# ESP32-S31 register map
Vendor: ESPRESSIF SYSTEMS (SHANGHAI) CO., LTD.; Series: ESP32 S-Series; File version: 1
CPU: RV32IMAFC r0p0, little endian, no MPU, FPU, 0 interrupt priority bits
Address unit: 32 bits
Registers are 32-bit, read-write, reset 0x0 unless marked. A register's access mark holds for its fields unless they carry their own. Offsets are from the block's base; [hi:lo] are bit positions; {n}, {i} and the like mark numbered series; 'fields as' and 'values as' point back to an identical list.

## MEMSPI2 — Memory SPI 2
Base 0x20502000
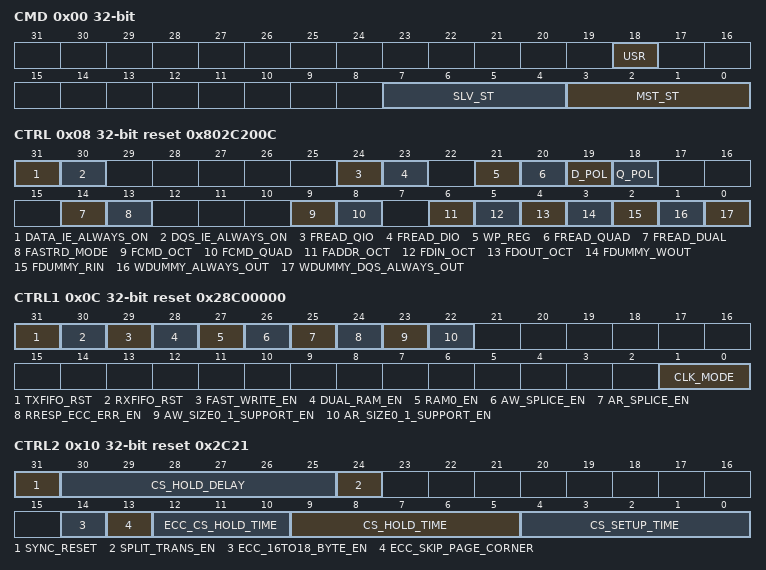
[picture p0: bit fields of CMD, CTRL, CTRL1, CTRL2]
0x00 CMD ro — SPI0 FSM status register
  [18] USR, [7:4] SLV_ST, [3:0] MST_ST
0x08 CTRL reset 0x802C200C — SPI0 control register.
  [31] DATA_IE_ALWAYS_ON, [30] DQS_IE_ALWAYS_ON, [24] FREAD_QIO, [23] FREAD_DIO, [21] WP_REG, [20] FREAD_QUAD, [19] D_POL, [18] Q_POL, [14] FREAD_DUAL, [13] FASTRD_MODE, [9] FCMD_OCT, [8] FCMD_QUAD, [6] FADDR_OCT, [5] FDIN_OCT, [4] FDOUT_OCT, [3] FDUMMY_WOUT, [2] FDUMMY_RIN, [1] WDUMMY_ALWAYS_OUT, [0] WDUMMY_DQS_ALWAYS_OUT
0x0C CTRL1 access per field reset 0x28C00000 — SPI0 control1 register.
  [31] TXFIFO_RST wo, [30] RXFIFO_RST wo, [29] FAST_WRITE_EN rw, [28] DUAL_RAM_EN ro, [27] RAM0_EN ro, [26] AW_SPLICE_EN rw, [25] AR_SPLICE_EN rw, [24] RRESP_ECC_ERR_EN rw, [23] AW_SIZE0_1_SUPPORT_EN rw, [22] AR_SIZE0_1_SUPPORT_EN rw, [1:0] CLK_MODE rw
0x10 CTRL2 access per field reset 0x2C21 — SPI0 control2 register.
  [31] SYNC_RESET wo, [30:25] CS_HOLD_DELAY rw, [24] SPLIT_TRANS_EN rw, [14] ECC_16TO18_BYTE_EN rw, [13] ECC_SKIP_PAGE_CORNER rw, [12:10] ECC_CS_HOLD_TIME rw, [9:5] CS_HOLD_TIME rw, [4:0] CS_SETUP_TIME rw
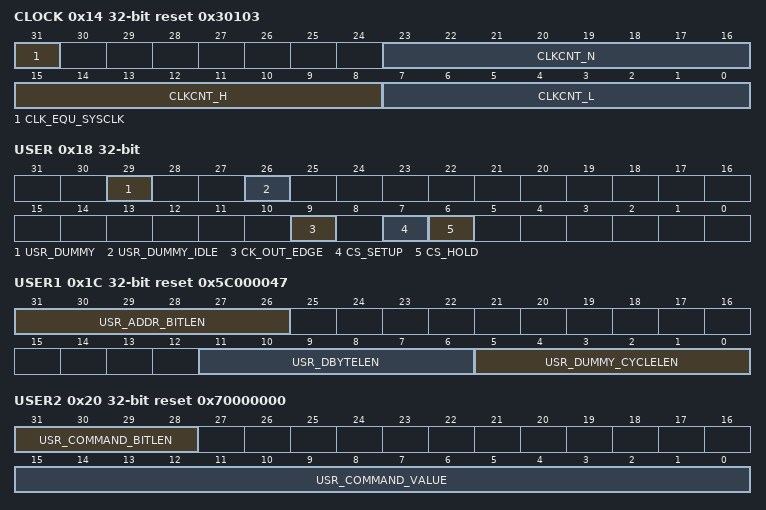
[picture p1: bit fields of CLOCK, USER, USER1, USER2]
0x14 CLOCK reset 0x30103 — SPI clock division control register.
  [31] CLK_EQU_SYSCLK, [23:16] CLKCNT_N, [15:8] CLKCNT_H, [7:0] CLKCNT_L
0x18 USER — SPI0 user register.
  [29] USR_DUMMY, [26] USR_DUMMY_IDLE, [9] CK_OUT_EDGE, [7] CS_SETUP, [6] CS_HOLD
0x1C USER1 access per field reset 0x5C000047 — SPI0 user1 register.
  [31:26] USR_ADDR_BITLEN rw, [11:6] USR_DBYTELEN ro, [5:0] USR_DUMMY_CYCLELEN rw
0x20 USER2 reset 0x70000000 — SPI0 user2 register.
  [31:28] USR_COMMAND_BITLEN, [15:0] USR_COMMAND_VALUE
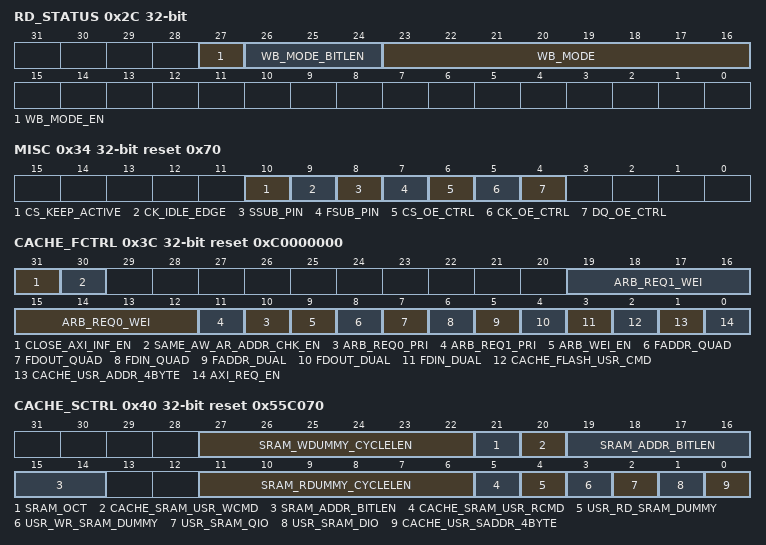
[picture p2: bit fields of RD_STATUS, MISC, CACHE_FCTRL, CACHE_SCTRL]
0x2C RD_STATUS — SPI0 read control register.
  [27] WB_MODE_EN, [26:24] WB_MODE_BITLEN, [23:16] WB_MODE
0x34 MISC access per field reset 0x70 — SPI0 misc register
  [10] CS_KEEP_ACTIVE rw, [9] CK_IDLE_EDGE rw, [8] SSUB_PIN ro, [7] FSUB_PIN ro, [6] CS_OE_CTRL rw, [5] CK_OE_CTRL rw, [4] DQ_OE_CTRL rw
0x3C CACHE_FCTRL reset 0xC0000000 — SPI0 bit mode control register.
  [31] CLOSE_AXI_INF_EN, [30] SAME_AW_AR_ADDR_CHK_EN, [4n+15:4n+12] ARB_REQ{n}_WEI (n=0..1), [n+10] ARB_REQ{n}_PRI (n=0..1), [9] ARB_WEI_EN, [8] FADDR_QUAD, [7] FDOUT_QUAD, [6] FDIN_QUAD, [5] FADDR_DUAL, [4] FDOUT_DUAL, [3] FDIN_DUAL, [2] CACHE_FLASH_USR_CMD, [1] CACHE_USR_ADDR_4BYTE, [0] AXI_REQ_EN
0x40 CACHE_SCTRL reset 0x55C070 — SPI0 external RAM control register
  [27:22] SRAM_WDUMMY_CYCLELEN, [21] SRAM_OCT, [20] CACHE_SRAM_USR_WCMD, [19:14] SRAM_ADDR_BITLEN, [11:6] SRAM_RDUMMY_CYCLELEN, [5] CACHE_SRAM_USR_RCMD, [4] USR_RD_SRAM_DUMMY, [3] USR_WR_SRAM_DUMMY, [2] USR_SRAM_QIO, [1] USR_SRAM_DIO, [0] CACHE_USR_SADDR_4BYTE
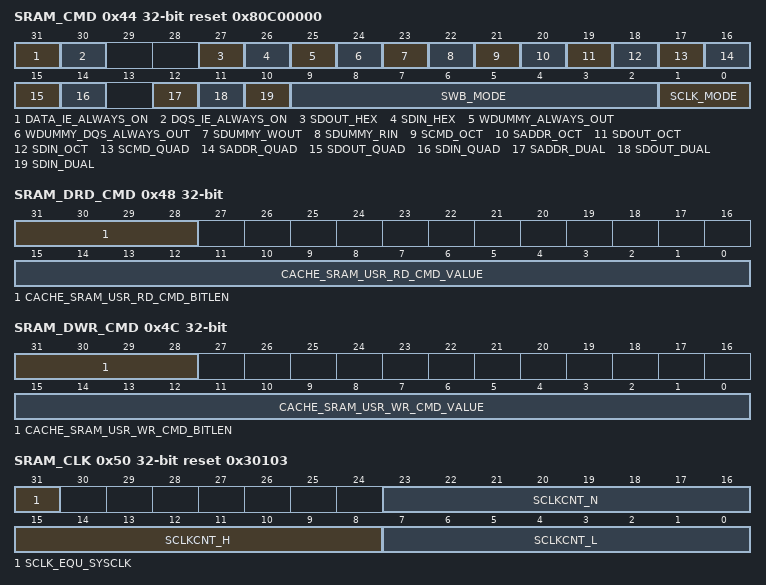
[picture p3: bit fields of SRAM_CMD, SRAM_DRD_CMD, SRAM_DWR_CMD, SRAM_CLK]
0x44 SRAM_CMD reset 0x80C00000 — SPI0 external RAM mode control register
  [31] DATA_IE_ALWAYS_ON, [30] DQS_IE_ALWAYS_ON, [27] SDOUT_HEX, [26] SDIN_HEX, [25] WDUMMY_ALWAYS_OUT, [24] WDUMMY_DQS_ALWAYS_OUT, [23] SDUMMY_WOUT, [22] SDUMMY_RIN, [21] SCMD_OCT, [20] SADDR_OCT, [19] SDOUT_OCT, [18] SDIN_OCT, [17] SCMD_QUAD, [16] SADDR_QUAD, [15] SDOUT_QUAD, [14] SDIN_QUAD, [12] SADDR_DUAL, [11] SDOUT_DUAL, [10] SDIN_DUAL, [9:2] SWB_MODE, [1:0] SCLK_MODE
0x48 SRAM_DRD_CMD — SPI0 external RAM DDR read command control register
  [31:28] CACHE_SRAM_USR_RD_CMD_BITLEN, [15:0] CACHE_SRAM_USR_RD_CMD_VALUE
0x4C SRAM_DWR_CMD — SPI0 external RAM DDR write command control register
  [31:28] CACHE_SRAM_USR_WR_CMD_BITLEN, [15:0] CACHE_SRAM_USR_WR_CMD_VALUE
0x50 SRAM_CLK reset 0x30103 — SPI0 external RAM clock control register
  [31] SCLK_EQU_SYSCLK, [23:16] SCLKCNT_N, [15:8] SCLKCNT_H, [7:0] SCLKCNT_L
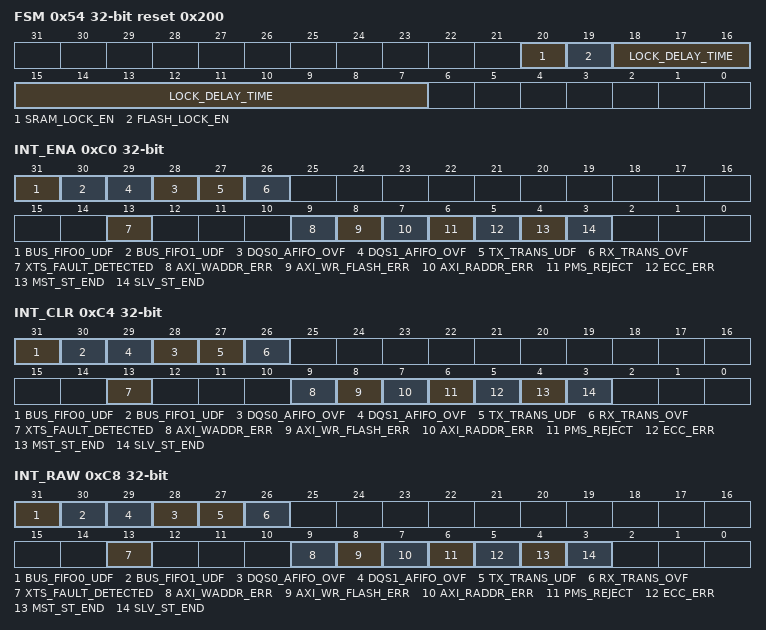
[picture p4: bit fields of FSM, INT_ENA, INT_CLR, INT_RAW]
0x54 FSM reset 0x200 — SPI0 FSM status register
  [20] SRAM_LOCK_EN, [19] FLASH_LOCK_EN, [18:7] LOCK_DELAY_TIME
0xC0 INT_ENA — SPI0 interrupt enable register
  [31] BUS_FIFO0_UDF, [30] BUS_FIFO1_UDF, [n+28] DQS{n}_AFIFO_OVF (n=0..1), [27] TX_TRANS_UDF, [26] RX_TRANS_OVF, [13] XTS_FAULT_DETECTED, [9] AXI_WADDR_ERR, [8] AXI_WR_FLASH_ERR, [7] AXI_RADDR_ERR, [6] PMS_REJECT, [5] ECC_ERR, [4] MST_ST_END, [3] SLV_ST_END
0xC4 INT_CLR wo — SPI0 interrupt clear register
  [31] BUS_FIFO0_UDF write-1-clears, [30] BUS_FIFO1_UDF write-1-clears, [n+28] DQS{n}_AFIFO_OVF (n=0..1) write-1-clears, [27] TX_TRANS_UDF write-1-clears, [26] RX_TRANS_OVF write-1-clears, [13] XTS_FAULT_DETECTED write-1-clears, [9] AXI_WADDR_ERR write-1-clears, [8] AXI_WR_FLASH_ERR write-1-clears, [7] AXI_RADDR_ERR write-1-clears, [6] PMS_REJECT write-1-clears, [5] ECC_ERR write-1-clears, [4] MST_ST_END write-1-clears, [3] SLV_ST_END write-1-clears
0xC8 INT_RAW — SPI0 interrupt raw register
  fields as INT_ENA
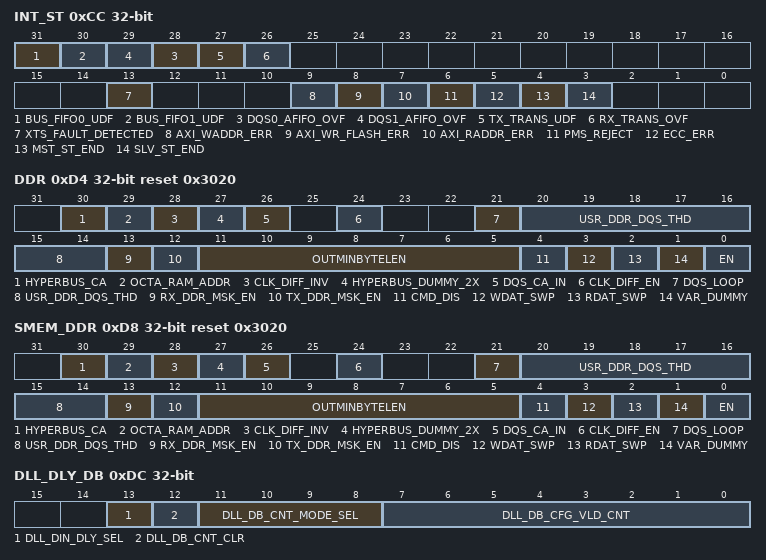
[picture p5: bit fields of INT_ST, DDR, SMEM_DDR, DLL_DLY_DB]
0xCC INT_ST ro — SPI0 interrupt status register
  fields as INT_ENA
0xD4 DDR reset 0x3020 — SPI0 flash DDR mode control register
  [30] HYPERBUS_CA, [29] OCTA_RAM_ADDR, [28] CLK_DIFF_INV, [27] HYPERBUS_DUMMY_2X, [26] DQS_CA_IN, [24] CLK_DIFF_EN, [21] DQS_LOOP, [20:14] USR_DDR_DQS_THD, [13] RX_DDR_MSK_EN, [12] TX_DDR_MSK_EN, [11:5] OUTMINBYTELEN, [4] CMD_DIS, [3] WDAT_SWP, [2] RDAT_SWP, [1] VAR_DUMMY, [0] EN
0xD8 SMEM_DDR reset 0x3020 — SPI0 external RAM DDR mode control register
  fields as DDR
0xDC DLL_DLY_DB — MSPI DLL function and debug configuration register
  [13] DLL_DIN_DLY_SEL, [12] DLL_DB_CNT_CLR, [11:8] DLL_DB_CNT_MODE_SEL, [7:0] DLL_DB_CFG_VLD_CNT
0xE0 DLL_DB_ST0 ro — MSPI DLL debug status0 register
  [31:0] DB_FIFO_CNT_H
0xE4 DLL_DB_ST1 ro — MSPI DLL debug status1 register
  [31:0] DB_FIFO_CNT_L
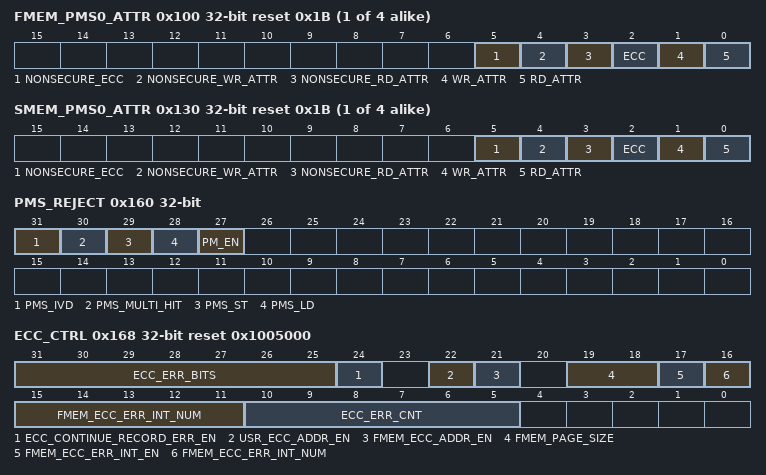
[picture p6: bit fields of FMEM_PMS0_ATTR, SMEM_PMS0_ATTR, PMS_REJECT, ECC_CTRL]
{0x100+4i} FMEM_PMS{i}_ATTR (i=0..3) reset 0x1B — SPI1 flash PMS section 0 attribute register
  [5] NONSECURE_ECC, [4] NONSECURE_WR_ATTR, [3] NONSECURE_RD_ATTR, [2] ECC, [1] WR_ATTR, [0] RD_ATTR
{0x110+4i} FMEM_PMS{i}_ADDR (i=0..3) — SPI1 flash PMS section 0 start address register
  [28:0] ADDR_S
{0x120+4i} FMEM_PMS{i}_SIZE (i=0..3) reset 0x1000 — SPI1 flash PMS section 0 start address register
  [16:0] SIZE
{0x130+4i} SMEM_PMS{i}_ATTR (i=0..3) reset 0x1B — SPI1 external RAM PMS section 0 attribute register
  fields as FMEM_PMS0_ATTR
{0x140+4i} SMEM_PMS{i}_ADDR (i=0..3) — SPI1 external RAM PMS section 0 start address register
  [28:0] ADDR_S
{0x150+4i} SMEM_PMS{i}_SIZE (i=0..3) reset 0x1000 — SPI1 external RAM PMS section 0 start address register
  [16:0] SIZE
0x160 PMS_REJECT — SPI1 access reject register
  [31] PMS_IVD, [30] PMS_MULTI_HIT, [29] PMS_ST, [28] PMS_LD, [27] PM_EN
0x164 PMS_REJECT_ADDR — SPI1 access reject addr register
  [28:0] REJECT_ADDR
0x168 ECC_CTRL reset 0x1005000 — MSPI ECC control register
  [31:25] ECC_ERR_BITS, [24] ECC_CONTINUE_RECORD_ERR_EN, [22] USR_ECC_ADDR_EN, [21] FMEM_ECC_ADDR_EN, [19:18] FMEM_PAGE_SIZE, [17] FMEM_ECC_ERR_INT_EN, [16:11] FMEM_ECC_ERR_INT_NUM, [10:5] ECC_ERR_CNT
0x16C ECC_ERR_ADDR — MSPI ECC error address register
  [28:0] ECC_ERR_ADDR
0x170 AXI_ERR_ADDR — SPI0 AXI request error address.
  [28:0] AXI_ERR_ADDR
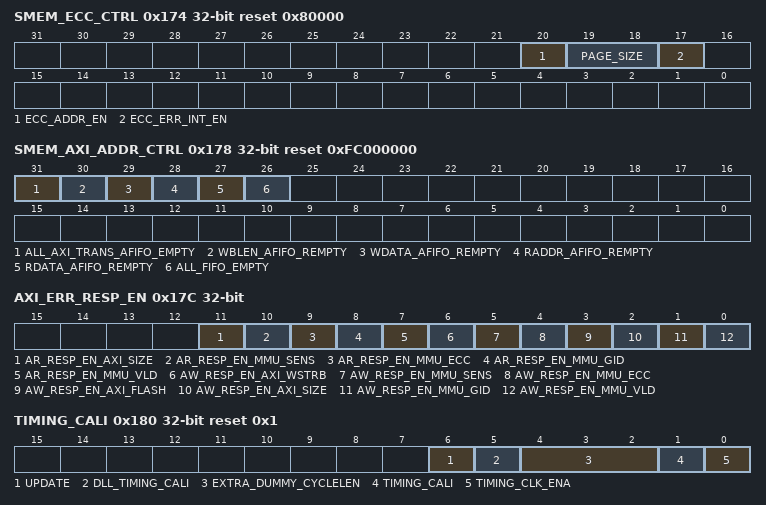
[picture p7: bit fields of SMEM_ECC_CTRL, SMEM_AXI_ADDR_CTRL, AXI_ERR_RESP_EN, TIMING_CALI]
0x174 SMEM_ECC_CTRL reset 0x80000 — MSPI ECC control register
  [20] ECC_ADDR_EN, [19:18] PAGE_SIZE, [17] ECC_ERR_INT_EN
0x178 SMEM_AXI_ADDR_CTRL ro reset 0xFC000000 — SPI0 AXI address control register
  [31] ALL_AXI_TRANS_AFIFO_EMPTY, [30] WBLEN_AFIFO_REMPTY, [29] WDATA_AFIFO_REMPTY, [28] RADDR_AFIFO_REMPTY, [27] RDATA_AFIFO_REMPTY, [26] ALL_FIFO_EMPTY
0x17C AXI_ERR_RESP_EN — SPI0 AXI error response enable register
  [11] AR_RESP_EN_AXI_SIZE, [10] AR_RESP_EN_MMU_SENS, [9] AR_RESP_EN_MMU_ECC, [8] AR_RESP_EN_MMU_GID, [7] AR_RESP_EN_MMU_VLD, [6] AW_RESP_EN_AXI_WSTRB, [5] AW_RESP_EN_MMU_SENS, [4] AW_RESP_EN_MMU_ECC, [3] AW_RESP_EN_AXI_FLASH, [2] AW_RESP_EN_AXI_SIZE, [1] AW_RESP_EN_MMU_GID, [0] AW_RESP_EN_MMU_VLD
0x180 TIMING_CALI access per field reset 0x1 — SPI0 flash timing calibration register
  [6] UPDATE wo, [5] DLL_TIMING_CALI rw, [4:2] EXTRA_DUMMY_CYCLELEN rw, [1] TIMING_CALI rw, [0] TIMING_CLK_ENA rw
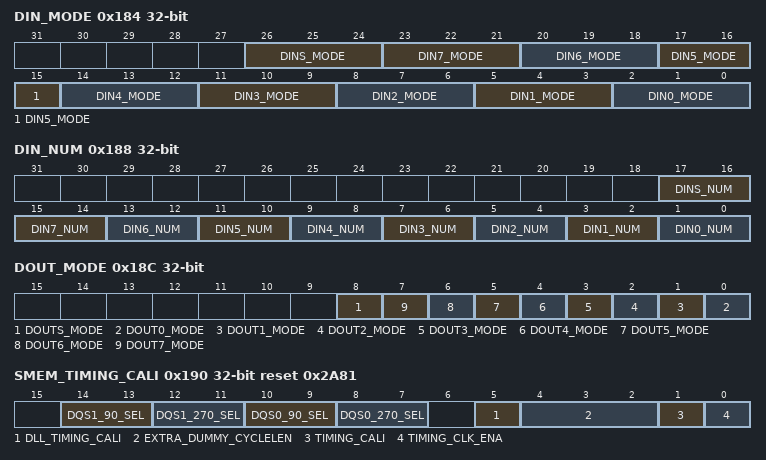
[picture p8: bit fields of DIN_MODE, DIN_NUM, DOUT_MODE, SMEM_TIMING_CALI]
0x184 DIN_MODE — MSPI flash input timing delay mode control register
  [26:24] DINS_MODE, [3n+2:3n] DIN{n}_MODE (n=0..7)
0x188 DIN_NUM — MSPI flash input timing delay number control register
  [17:16] DINS_NUM, [2n+1:2n] DIN{n}_NUM (n=0..7)
0x18C DOUT_MODE — MSPI flash output timing adjustment control register
  [8] DOUTS_MODE, [n] DOUT{n}_MODE (n=0..7)
0x190 SMEM_TIMING_CALI reset 0x2A81 — MSPI external RAM timing calibration register
  [14:13] DQS1_90_SEL, [12:11] DQS1_270_SEL, [10:9] DQS0_90_SEL, [8:7] DQS0_270_SEL, [5] DLL_TIMING_CALI, [4:2] EXTRA_DUMMY_CYCLELEN, [1] TIMING_CALI, [0] TIMING_CLK_ENA
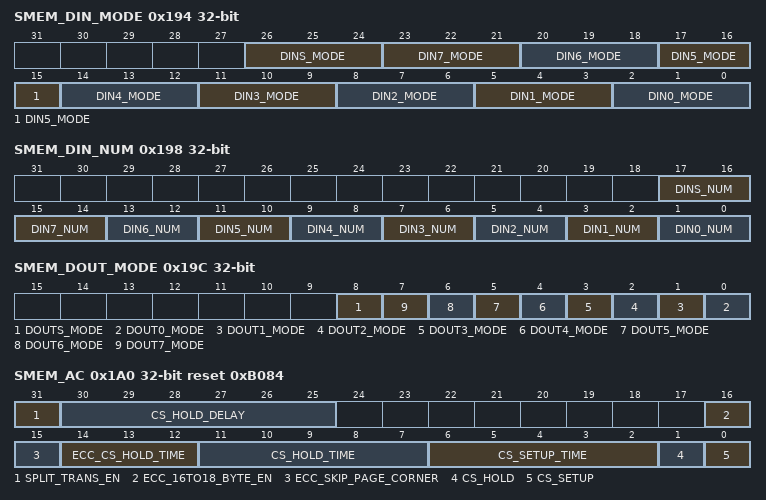
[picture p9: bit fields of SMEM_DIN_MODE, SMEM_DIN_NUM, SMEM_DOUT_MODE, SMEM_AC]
0x194 SMEM_DIN_MODE — MSPI external RAM input timing delay mode control register
  [26:24] DINS_MODE, [3n+2:3n] DIN{n}_MODE (n=0..7)
0x198 SMEM_DIN_NUM — MSPI external RAM input timing delay number control register
  [17:16] DINS_NUM, [2n+1:2n] DIN{n}_NUM (n=0..7)
0x19C SMEM_DOUT_MODE — MSPI external RAM output timing adjustment control register
  [8] DOUTS_MODE, [n] DOUT{n}_MODE (n=0..7)
0x1A0 SMEM_AC reset 0xB084 — MSPI external RAM ECC and SPI CS timing control register
  [31] SPLIT_TRANS_EN, [30:25] CS_HOLD_DELAY, [16] ECC_16TO18_BYTE_EN, [15] ECC_SKIP_PAGE_CORNER, [14:12] ECC_CS_HOLD_TIME, [11:7] CS_HOLD_TIME, [6:2] CS_SETUP_TIME, [1] CS_HOLD, [0] CS_SETUP
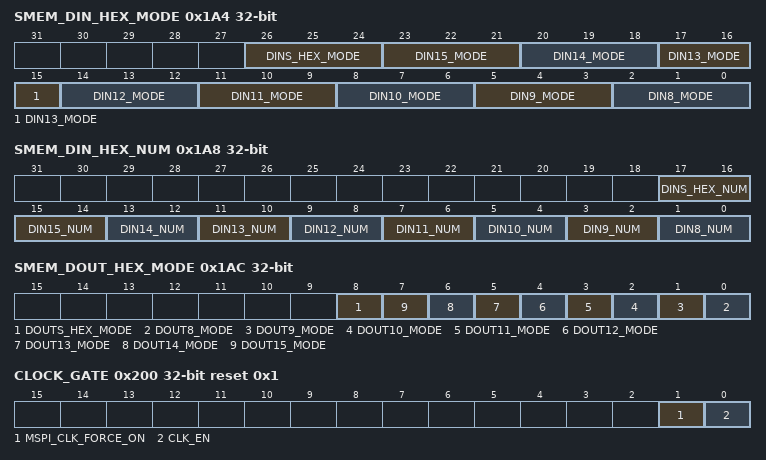
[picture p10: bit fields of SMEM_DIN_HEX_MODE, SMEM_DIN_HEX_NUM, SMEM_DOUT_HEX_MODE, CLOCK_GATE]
0x1A4 SMEM_DIN_HEX_MODE — MSPI 16x external RAM input timing delay mode control register
  [26:24] DINS_HEX_MODE, [3n-22:3n-24] DIN{n}_MODE (n=8..15)
0x1A8 SMEM_DIN_HEX_NUM — MSPI 16x external RAM input timing delay number control register
  [17:16] DINS_HEX_NUM, [2n-15:2n-16] DIN{n}_NUM (n=8..15)
0x1AC SMEM_DOUT_HEX_MODE — MSPI 16x external RAM output timing adjustment control register
  [8] DOUTS_HEX_MODE, [n-8] DOUT{n}_MODE (n=8..15)
0x200 CLOCK_GATE reset 0x1 — SPI0 clock gate register
  [1] MSPI_CLK_FORCE_ON, [0] CLK_EN
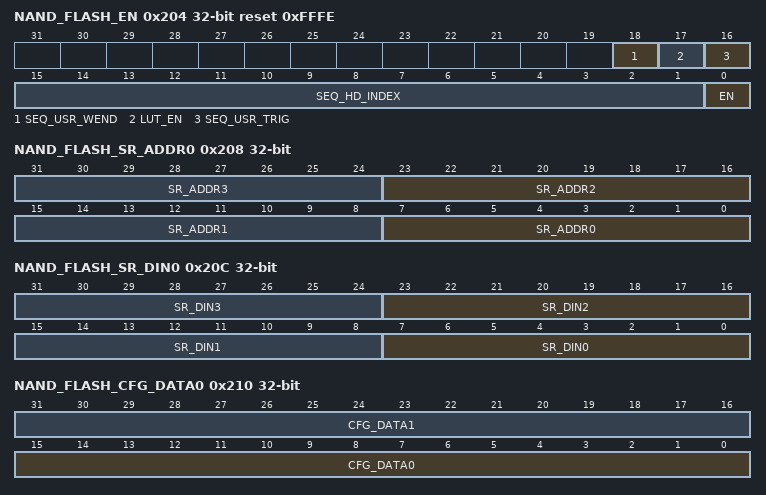
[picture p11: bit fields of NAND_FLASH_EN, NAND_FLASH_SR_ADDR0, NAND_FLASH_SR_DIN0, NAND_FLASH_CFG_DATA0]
0x204 NAND_FLASH_EN ro reset 0xFFFE — NAND FLASH control register
  [18] SEQ_USR_WEND, [17] LUT_EN, [16] SEQ_USR_TRIG, [15:1] SEQ_HD_INDEX, [0] EN
0x208 NAND_FLASH_SR_ADDR0 ro — NAND FLASH SPI SEQ control register
  [8n+7:8n] SR_ADDR{n} (n=0..3)
0x20C NAND_FLASH_SR_DIN0 ro — NAND FLASH SPI SEQ control register
  [8n+7:8n] SR_DIN{n} (n=0..3)
0x210 NAND_FLASH_CFG_DATA0 ro — NAND FLASH SPI SEQ control register
  [16n+15:16n] CFG_DATA{n} (n=0..1)
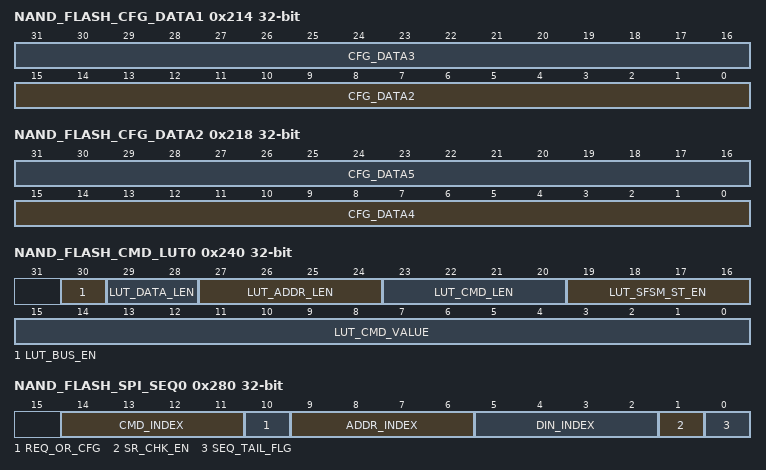
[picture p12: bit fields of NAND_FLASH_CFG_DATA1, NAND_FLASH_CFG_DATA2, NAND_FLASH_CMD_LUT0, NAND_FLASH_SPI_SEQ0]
0x214 NAND_FLASH_CFG_DATA1 ro — NAND FLASH SPI SEQ control register
  [16n-17:16n-32] CFG_DATA{n} (n=2..3)
0x218 NAND_FLASH_CFG_DATA2 ro — NAND FLASH SPI SEQ control register
  [16n-49:16n-64] CFG_DATA{n} (n=4..5)
0x240 NAND_FLASH_CMD_LUT0 ro — MSPI NAND FLASH CMD LUT control register
  [30] LUT_BUS_EN, [29:28] LUT_DATA_LEN, [27:24] LUT_ADDR_LEN, [23:20] LUT_CMD_LEN, [19:16] LUT_SFSM_ST_EN, [15:0] LUT_CMD_VALUE
0x280 NAND_FLASH_SPI_SEQ0 ro — NAND FLASH SPI SEQ control register
  [14:11] CMD_INDEX, [10] REQ_OR_CFG, [9:6] ADDR_INDEX, [5:2] DIN_INDEX, [1] SR_CHK_EN, [0] SEQ_TAIL_FLG
0x300 XTS_PLAIN_BASE — The base address of the memory that stores plaintext in Manual Encryption
  [31:0] XTS_PLAIN
0x340 XTS_LINESIZE — Manual Encryption Line-Size register
  [1:0] XTS_LINESIZE
0x344 XTS_DESTINATION — Manual Encryption destination register
  [0] XTS_DESTINATION
0x348 XTS_PHYSICAL_ADDRESS — Manual Encryption physical address register
  [29:0] XTS_PHYSICAL_ADDRESS
0x34C XTS_TRIGGER wo — Manual Encryption physical address register
  [0] XTS_TRIGGER
0x350 XTS_RELEASE wo — Manual Encryption physical address register
  [0] XTS_RELEASE
0x354 XTS_DESTROY wo — Manual Encryption physical address register
  [0] XTS_DESTROY
0x358 XTS_STATE ro — Manual Encryption physical address register
  [1:0] XTS_STATE
0x35C XTS_DATE reset 0x20210907 — Manual Encryption version register
  [29:0] XTS_DATE
0x37C MMU_ITEM_CONTENT reset 0x37C — MSPI-MMU item content register
  [13] SENSITIVE — Decrypt via flash encryption when set (flash MMU)
  [12] VALID — Entry is valid when set (flash MMU)
  [12] SPIRAM_SENSITIVE — Decrypt via cache encryption when set (SPIRAM MMU)
  [11] SPIRAM_VALID — Entry is valid when set (SPIRAM MMU)
  [10] ACCESS_SPIRAM — Map to SPIRAM/PSRAM when set (flash when clear)
  [9:0] PADDR — Physical page number
0x380 MMU_ITEM_INDEX — MSPI-MMU item index register
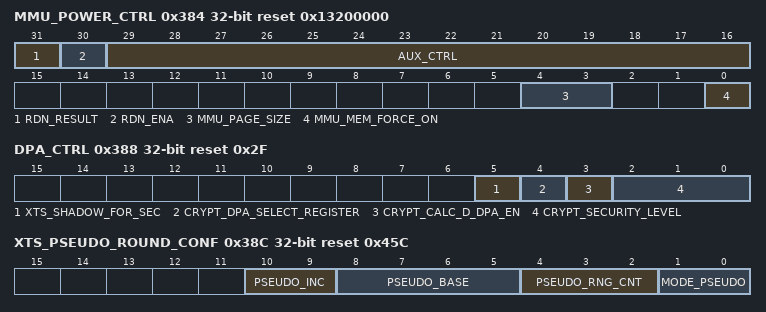
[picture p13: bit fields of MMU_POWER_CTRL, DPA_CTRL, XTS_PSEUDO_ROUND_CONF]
0x384 MMU_POWER_CTRL access per field reset 0x13200000 — MSPI MMU power control register
  [31] RDN_RESULT ro, [30] RDN_ENA rw, [29:16] AUX_CTRL rw, [4:3] MMU_PAGE_SIZE rw, [0] MMU_MEM_FORCE_ON rw
0x388 DPA_CTRL reset 0x2F — SPI memory cryption DPA register
  [5] XTS_SHADOW_FOR_SEC, [4] CRYPT_DPA_SELECT_REGISTER, [3] CRYPT_CALC_D_DPA_EN, [2:0] CRYPT_SECURITY_LEVEL
0x38C XTS_PSEUDO_ROUND_CONF reset 0x45C — SPI memory cryption PSEUDO register
  [10:9] PSEUDO_INC, [8:5] PSEUDO_BASE, [4:2] PSEUDO_RNG_CNT, [1:0] MODE_PSEUDO
0x3F0 REGISTERRND_ECO_HIGH reset 0x37C — MSPI ECO high register
0x3F4 REGISTERRND_ECO_LOW reset 0x37C — MSPI ECO low register
0x3FC DATE reset 0x2509030 — SPI0 version control register
  [27:0] DATE
